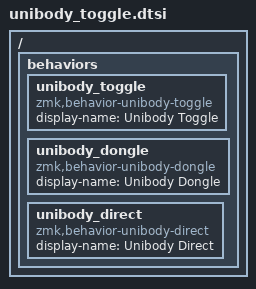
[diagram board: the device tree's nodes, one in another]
/*
 * Copyright (c) 2026 The ZMK Contributors
 *
 * SPDX-License-Identifier: MIT
 */

/ {
    behaviors {
        unibody_toggle: unibody_toggle {
            compatible = "zmk,behavior-unibody-toggle";
            #binding-cells = <0>;
            display-name = "Unibody Toggle";
        };

        unibody_dongle: unibody_dongle {
            compatible = "zmk,behavior-unibody-dongle";
            #binding-cells = <0>;
            display-name = "Unibody Dongle";
        };

        unibody_direct: unibody_direct {
            compatible = "zmk,behavior-unibody-direct";
            #binding-cells = <0>;
            display-name = "Unibody Direct";
        };
    };
};
